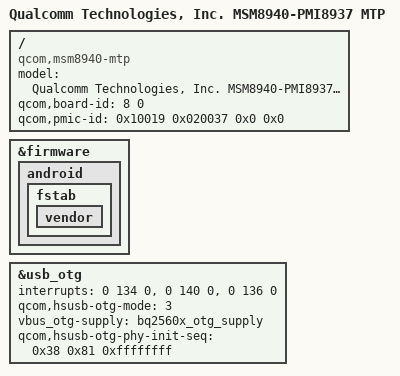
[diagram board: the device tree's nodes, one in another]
/*
 * Copyright (c) 2016, The Linux Foundation. All rights reserved.
 *
 * This program is free software; you can redistribute it and/or modify
 * it under the terms of the GNU General Public License version 2 and
 * only version 2 as published by the Free Software Foundation.
 *
 * This program is distributed in the hope that it will be useful,
 * but WITHOUT ANY WARRANTY; without even the implied warranty of
 * MERCHANTABILITY or FITNESS FOR A PARTICULAR PURPOSE.  See the
 * GNU General Public License for more details.
 */

/dts-v1/;

#include "../qcom/msm8940.dtsi"
#include "../qcom/msm8940-pmi8937-mtp.dtsi"
#include "common/common.dtsi"
#include "ugg/ugg.dtsi"

/ {
	model = "Qualcomm Technologies, Inc. MSM8940-PMI8937 MTP";
	compatible = "qcom,msm8940-mtp", "qcom,msm8940", "qcom,mtp";
	qcom,board-id= <8 0>;
	qcom,pmic-id = <0x10019 0x020037 0x0 0x0>;
};

&firmware {
	android {
		fstab {
			vendor {
                		status = "ok";
			};
		};
	};
};

&usb_otg{
	interrupts = <0 134 0>,<0 140 0>,<0 136 0>;
	interrupt-names = "core_irq", "async_irq","phy_irq";
	qcom,hsusb-otg-mode = <3>;
	vbus_otg-supply = <&bq2560x_otg_supply>;
	qcom,hsusb-otg-phy-init-seq =
	<0x38 0x81 0xffffffff>;
};
